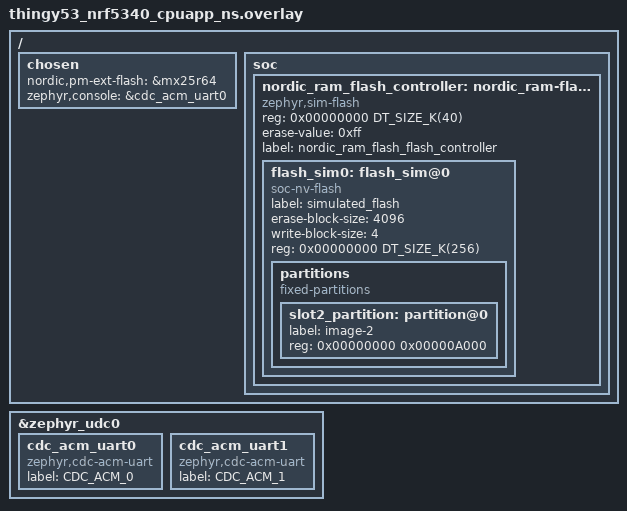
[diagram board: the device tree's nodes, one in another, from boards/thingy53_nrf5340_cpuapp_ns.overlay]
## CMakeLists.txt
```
#
# Copyright (c) 2018 Nordic Semiconductor
#
# SPDX-License-Identifier: LicenseRef-Nordic-5-Clause
#
cmake_minimum_required(VERSION 3.20.0)

find_package(Zephyr REQUIRED HINTS $ENV{ZEPHYR_BASE})
project(NONE)

# NORDIC SDK APP START
target_sources(app PRIVATE
  src/main.c
  src/protocol.c
  src/device_identification.c
  src/operation_command.c
  src/setting_command.c
  src/setting_command.c
  src/pressure_sensor.c
  deps/BMP180_driver/bmp180.c
)

# NORDIC SDK APP END

zephyr_library_include_directories(.)
zephyr_library_include_directories(deps)
```

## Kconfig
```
#
# Copyright (c) 2018 Nordic Semiconductor
#
# SPDX-License-Identifier: LicenseRef-Nordic-5-Clause
#

source "Kconfig.zephyr"

menu "Nordic UART BLE GATT service sample"

config BT_NUS_THREAD_STACK_SIZE
	int "Thread stack size"
	default 1024
	help
	  Stack size used in each of the two threads

config BT_NUS_UART_BUFFER_SIZE
	int "UART payload buffer element size"
	default 40
	help
	  Size of the payload buffer in each RX and TX FIFO element

config BT_NUS_SECURITY_ENABLED
	bool "Enable security"
	default y
	select BT_SMP
	help
	  "Enable BLE security for the UART service"

config BT_NUS_UART_DEV
	string "UART device name"
	default "UART_0"
	help
	  Name of the used UART device. The sample uses uart0 by default.
	  The UART device should not be used as logger backend.

config BT_NUS_UART_RX_WAIT_TIME
	int "Timeout for UART RX complete event"
	default 50
	help
	  Wait for RX complete event time in milliseconds

config BT_NUS_UART_ASYNC_ADAPTER
	bool "Enable UART async adapter"
	select SERIAL_SUPPORT_ASYNC
	help
	  Enables asynchronous adapter for UART drives that supports only
	  IRQ interface.

endmenu
```

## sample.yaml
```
sample:
  name: BLE UART service
  description: Bluetooth Low Energy UART service sample
tests:
  samples.bluetooth.peripheral_uart:
    build_only: true
    platform_allow: nrf51dk_nrf51422 nrf52dk_nrf52832 nrf52840dk_nrf52840
      nrf5340dk_nrf5340_cpuapp nrf5340dk_nrf5340_cpuapp_ns thingy53_nrf5340_cpuapp
      thingy53_nrf5340_cpuapp_ns nrf21540dk_nrf52840
    integration_platforms:
      - nrf51dk_nrf51422
      - nrf52dk_nrf52832
      - nrf52840dk_nrf52840
      - nrf5340dk_nrf5340_cpuapp
      - nrf5340dk_nrf5340_cpuapp_ns
      - thingy53_nrf5340_cpuapp
      - thingy53_nrf5340_cpuapp_ns
      - nrf21540dk_nrf52840
    tags: bluetooth ci_build
  samples.bluetooth.peripheral_uart_minimal:
    extra_args: OVERLAY_CONFIG=prj_minimal.conf
    build_only: true
    platform_allow: nrf52dk_nrf52810 nrf52840dk_nrf52811 nrf52833dk_nrf52820
    integration_platforms:
      - nrf52dk_nrf52810
      - nrf52840dk_nrf52811
      - nrf52833dk_nrf52820
    tags: bluetooth ci_build
  samples.bluetooth.peripheral_uart_cdc:
    extra_args: OVERLAY_CONFIG=prj_cdc.conf
                DTC_OVERLAY_FILE="usb.overlay"
    build_only: true
    platform_allow: nrf52840dk_nrf52840 nrf52833dk_nrf52833
    integration_platforms:
      - nrf52840dk_nrf52840
      - nrf52833dk_nrf52833
    tags: bluetooth ci_build
```

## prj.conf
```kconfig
#
# Copyright (c) 2018 Nordic Semiconductor
#
# SPDX-License-Identifier: LicenseRef-Nordic-5-Clause
#

# Enable the UART driver
CONFIG_UART_ASYNC_API=y
CONFIG_NRFX_UARTE0=y
CONFIG_SERIAL=y

# Enable the I2C driver
CONFIG_NRFX_TWI0=y
CONFIG_I2C=y

# Enable the PWM driver
CONFIG_NRFX_PWM0=y

CONFIG_GPIO=y

CONFIG_HEAP_MEM_POOL_SIZE=2048

CONFIG_BT=y
CONFIG_BT_PERIPHERAL=y
CONFIG_BT_DEVICE_NAME="Pressure Biofeedback App"
CONFIG_BT_DEVICE_APPEARANCE=833
CONFIG_BT_MAX_CONN=1
CONFIG_BT_MAX_PAIRED=1

# Enable the NUS service
CONFIG_BT_NUS=y
CONFIG_BT_NUS_SECURITY_ENABLED=n

# Enable bonding
CONFIG_BT_SETTINGS=y
CONFIG_FLASH=y
CONFIG_FLASH_PAGE_LAYOUT=y
CONFIG_FLASH_MAP=y
CONFIG_NVS=y
CONFIG_SETTINGS=y

# Enable DK LED and Buttons library
CONFIG_DK_LIBRARY=y

# This example requires more workqueue stack
CONFIG_SYSTEM_WORKQUEUE_STACK_SIZE=2048

# Config logger
CONFIG_LOG=y
CONFIG_USE_SEGGER_RTT=y
CONFIG_LOG_BACKEND_RTT=y
CONFIG_LOG_BACKEND_UART=n

CONFIG_ASSERT=y
```

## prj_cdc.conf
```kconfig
#
# Copyright (c) 2021 Nordic Semiconductor
#
# SPDX-License-Identifier: LicenseRef-Nordic-5-Clause
#

# Enable the UART driver
CONFIG_UART_LINE_CTRL=y
CONFIG_UART_INTERRUPT_DRIVEN=y
CONFIG_BT_NUS_UART_ASYNC_ADAPTER=y
CONFIG_USB_DEVICE_STACK=y
CONFIG_USB_CDC_ACM=y
CONFIG_BT_NUS_UART_DEV="CDC_ACM_0"

# Disable the UARTE0 enabled in default project configuration
CONFIG_NRFX_UARTE0=n
CONFIG_UART_NRFX=n
```

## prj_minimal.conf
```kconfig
#
# Copyright (c) 2021 Nordic Semiconductor
#
# SPDX-License-Identifier: LicenseRef-Nordic-5-Clause
#

# Enable the UART driver
CONFIG_UART_ASYNC_API=y
CONFIG_NRFX_UARTE0=y
CONFIG_SERIAL=y

CONFIG_HEAP_MEM_POOL_SIZE=2048

CONFIG_BT=y
CONFIG_BT_PERIPHERAL=y
CONFIG_BT_DEVICE_NAME="Nordic_UART_Service"
CONFIG_BT_DEVICE_APPEARANCE=833
CONFIG_BT_MAX_CONN=1
CONFIG_BT_MAX_PAIRED=1

# Enable the NUS service
CONFIG_BT_NUS=y

# Enable bonding
CONFIG_BT_SETTINGS=y
CONFIG_FLASH=y
CONFIG_FLASH_PAGE_LAYOUT=y
CONFIG_FLASH_MAP=y
CONFIG_NVS=y
CONFIG_SETTINGS=y

# Enable DK LED and Buttons library
CONFIG_DK_LIBRARY=y

# Drivers and peripherals
CONFIG_I2C=n
CONFIG_WATCHDOG=n
CONFIG_PINMUX=n
CONFIG_SPI=n
CONFIG_GPIO=n

# Power management
CONFIG_PM=n

# Interrupts
CONFIG_DYNAMIC_INTERRUPTS=n
CONFIG_IRQ_OFFLOAD=n

# Memory protection
CONFIG_THREAD_STACK_INFO=n
CONFIG_THREAD_CUSTOM_DATA=n
CONFIG_FPU=n

# Boot
CONFIG_BOOT_BANNER=n
CONFIG_BOOT_DELAY=0

# Console
CONFIG_CONSOLE=n
CONFIG_UART_CONSOLE=n
CONFIG_STDOUT_CONSOLE=n
CONFIG_PRINTK=n
CONFIG_EARLY_CONSOLE=n

# Build
CONFIG_SIZE_OPTIMIZATIONS=y

# ARM
CONFIG_ARM_MPU=n

# In order to correctly tune the stack sizes for the threads the following
# Configurations can enabled to print the current use:
#CONFIG_THREAD_NAME=y
#CONFIG_THREAD_ANALYZER=y
#CONFIG_THREAD_ANALYZER_AUTO=y
#CONFIG_THREAD_ANALYZER_RUN_UNLOCKED=y
#CONFIG_THREAD_ANALYZER_USE_PRINTK=y
#CONFIG_CONSOLE=y
#CONFIG_UART_CONSOLE=y
#CONFIG_SERIAL=y
#CONFIG_PRINTK=y

# Example output of thread analyzer
#SDC RX              : unused 800 usage 224 / 1024 (21 %)
#BT ECC              : unused 216 usage 888 / 1104 (80 %)
#BT RX               : unused 1736 usage 464 / 2200 (21 %)
#BT TX               : unused 1008 usage 528 / 1536 (34 %)
#ble_write_thread_id : unused 688 usage 336 / 1024 (32 %)
#sysworkq            : unused 1912 usage 136 / 2048 (6 %)
#MPSL signal         : unused 928 usage 96 / 1024 (9 %)
#idle 00             : unused 224 usage 96 / 320 (30 %)
#main                : unused 568 usage 456 / 1024 (44 %)
CONFIG_BT_CTLR_SDC_RX_STACK_SIZE=324
CONFIG_BT_RX_STACK_SIZE=1024
CONFIG_BT_HCI_TX_STACK_SIZE_WITH_PROMPT=y
CONFIG_BT_HCI_TX_STACK_SIZE=640
CONFIG_SYSTEM_WORKQUEUE_STACK_SIZE=512
CONFIG_MPSL_SIGNAL_STACK_SIZE=256
CONFIG_MAIN_STACK_SIZE=640
CONFIG_IDLE_STACK_SIZE=128
CONFIG_ISR_STACK_SIZE=1024
CONFIG_BT_NUS_THREAD_STACK_SIZE=512

# Disable features not needed
CONFIG_TIMESLICING=n
CONFIG_MINIMAL_LIBC_MALLOC=n
CONFIG_LOG=n
CONFIG_ASSERT=n

# Disable Bluetooth features not needed
CONFIG_BT_DEBUG_NONE=y
CONFIG_BT_ASSERT=n
CONFIG_BT_DATA_LEN_UPDATE=n
CONFIG_BT_PHY_UPDATE=n
CONFIG_BT_GATT_CACHING=n
CONFIG_BT_GATT_SERVICE_CHANGED=n
CONFIG_BT_GAP_PERIPHERAL_PREF_PARAMS=n
CONFIG_BT_SETTINGS_CCC_LAZY_LOADING=y
CONFIG_BT_HCI_VS_EXT=n

# Disable Bluetooth controller features not needed
CONFIG_BT_CTLR_PRIVACY=n
CONFIG_BT_CTLR_PHY_2M=n

# Reduce Bluetooth buffers
CONFIG_BT_BUF_EVT_DISCARDABLE_COUNT=1
CONFIG_BT_BUF_EVT_DISCARDABLE_SIZE=43
CONFIG_BT_BUF_EVT_RX_COUNT=2

CONFIG_BT_CONN_TX_MAX=2
CONFIG_BT_L2CAP_TX_BUF_COUNT=2
CONFIG_BT_CTLR_RX_BUFFERS=1
CONFIG_BT_BUF_ACL_TX_COUNT=3
CONFIG_BT_BUF_ACL_TX_SIZE=27
```

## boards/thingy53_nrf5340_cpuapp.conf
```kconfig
#
# Copyright (c) 2021 Nordic Semiconductor ASA
#
# SPDX-License-Identifier: LicenseRef-Nordic-5-Clause
#
################################################################################
# Application overlay - Thingy:53 DFU

CONFIG_MCUMGR=y
CONFIG_MCUMGR_SMP_BT=y
CONFIG_MCUMGR_SMP_BT_AUTHEN=n
CONFIG_MCUMGR_SMP_BT_CONN_PARAM_CONTROL=y

CONFIG_MCUMGR_CMD_IMG_MGMT=y
CONFIG_MCUMGR_CMD_OS_MGMT=y

# Enable custom SMP request to erase settings partition.
CONFIG_MCUMGR_GRP_ZEPHYR_BASIC=y
CONFIG_MCUMGR_GRP_BASIC_CMD_STORAGE_ERASE=y

# Increase system workqueue stack size to prevent stack overflows while handling
# SMP requests.
CONFIG_SYSTEM_WORKQUEUE_STACK_SIZE=2800

CONFIG_BT_L2CAP_TX_MTU=498
CONFIG_BT_BUF_ACL_TX_SIZE=251
CONFIG_BT_BUF_ACL_RX_SIZE=502

# Use connection parameters that ensure quick data transfer
CONFIG_BT_PERIPHERAL_PREF_MIN_INT=6
CONFIG_BT_PERIPHERAL_PREF_MAX_INT=6
CONFIG_BT_PERIPHERAL_PREF_LATENCY=99
CONFIG_BT_PERIPHERAL_PREF_TIMEOUT=400

# LEDs are not inverted on Thingy:53
CONFIG_DK_LIBRARY_INVERT_LEDS=n

################################################################################
# Bootloader configuration

CONFIG_BOOTLOADER_MCUBOOT=y
CONFIG_MCUBOOT_IMAGE_VERSION="1.0.0+0"
CONFIG_UPDATEABLE_IMAGE_NUMBER=2

CONFIG_IMG_MANAGER=y
CONFIG_MCUBOOT_IMG_MANAGER=y
CONFIG_IMG_ERASE_PROGRESSIVELY=y

################################################################################
# External flash configuration

CONFIG_NORDIC_QSPI_NOR=y
CONFIG_NORDIC_QSPI_NOR_FLASH_LAYOUT_PAGE_SIZE=4096
CONFIG_NORDIC_QSPI_NOR_STACK_WRITE_BUFFER_SIZE=16

# FLASH nop device is enabled to prevent bus faults when mcumgr tries to access
# simulated partition with network core image data.
CONFIG_FLASH_NOP_DEVICE=y

################################################################################
# Enable USB CDC ACM

CONFIG_USB_DEVICE_STACK=y
CONFIG_USB_DEVICE_PRODUCT="Thingy:53 Nordic UART Service sample"
CONFIG_USB_DEVICE_VID=0x1915
CONFIG_USB_DEVICE_PID=0x530E
CONFIG_USB_COMPOSITE_DEVICE=y
CONFIG_USB_CDC_ACM=y
CONFIG_USB_CDC_ACM_LOG_LEVEL_ERR=y
CONFIG_USB_DEVICE_LOG_LEVEL_ERR=y

CONFIG_LOG_BACKEND_UART=y
CONFIG_LOG_PRINTK=y
CONFIG_LOG_PROCESS_THREAD_STACK_SIZE=1024
CONFIG_LOG_PROCESS_THREAD_STARTUP_DELAY_MS=4000
CONFIG_USE_SEGGER_RTT=n
CONFIG_LOG_BACKEND_RTT=n

CONFIG_BT_NUS_UART_ASYNC_ADAPTER=y
CONFIG_BT_NUS_UART_DEV="CDC_ACM_1"
CONFIG_UART_INTERRUPT_DRIVEN=y

# Disable the UARTE0 enabled in default project configuration
CONFIG_NRFX_UARTE0=n
CONFIG_UART_NRFX=n
```

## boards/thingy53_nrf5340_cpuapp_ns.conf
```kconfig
#
# Copyright (c) 2021 Nordic Semiconductor ASA
#
# SPDX-License-Identifier: LicenseRef-Nordic-5-Clause
#
################################################################################
# Application overlay - Thingy:53 DFU

CONFIG_MCUMGR=y
CONFIG_MCUMGR_SMP_BT=y
CONFIG_MCUMGR_SMP_BT_AUTHEN=n
CONFIG_MCUMGR_SMP_BT_CONN_PARAM_CONTROL=y

CONFIG_MCUMGR_CMD_IMG_MGMT=y
CONFIG_MCUMGR_CMD_OS_MGMT=y

# Enable MCUmgr Packet Reassembly feature over Bluetooth and its
# configuration dependencies. MCUmgr buffer size is optimized to fit one SMP
# packet divided into five Bluetooth Write Commands, transmitted with the
# maximum possible MTU value: 498 bytes.
CONFIG_MCUMGR_SMP_REASSEMBLY_BT=y
CONFIG_MCUMGR_BUF_SIZE=2475
CONFIG_OS_MGMT_MCUMGR_PARAMS=y

# Enable custom SMP request to erase settings partition.
CONFIG_MCUMGR_GRP_ZEPHYR_BASIC=y
CONFIG_MCUMGR_GRP_BASIC_CMD_STORAGE_ERASE=y

# Increase system workqueue stack size to prevent stack overflows while handling
# SMP requests.
CONFIG_SYSTEM_WORKQUEUE_STACK_SIZE=4096

CONFIG_BT_L2CAP_TX_MTU=498
CONFIG_BT_BUF_ACL_TX_SIZE=251
CONFIG_BT_BUF_ACL_RX_SIZE=502

# Use connection parameters that ensure quick data transfer
CONFIG_BT_PERIPHERAL_PREF_MIN_INT=6
CONFIG_BT_PERIPHERAL_PREF_MAX_INT=6
CONFIG_BT_PERIPHERAL_PREF_LATENCY=99
CONFIG_BT_PERIPHERAL_PREF_TIMEOUT=400

################################################################################
# Bootloader configuration

CONFIG_BOOTLOADER_MCUBOOT=y
CONFIG_MCUBOOT_IMAGE_VERSION="2.0.0+0"
CONFIG_UPDATEABLE_IMAGE_NUMBER=2

CONFIG_IMG_MANAGER=y
CONFIG_MCUBOOT_IMG_MANAGER=y
CONFIG_IMG_ERASE_PROGRESSIVELY=y

################################################################################
# External flash configuration

CONFIG_NORDIC_QSPI_NOR=y
CONFIG_NORDIC_QSPI_NOR_FLASH_LAYOUT_PAGE_SIZE=4096
CONFIG_NORDIC_QSPI_NOR_STACK_WRITE_BUFFER_SIZE=16

################################################################################
# Enable USB CDC ACM

CONFIG_USB_DEVICE_STACK=y
CONFIG_USB_DEVICE_REMOTE_WAKEUP=n
CONFIG_USB_DEVICE_PRODUCT="Thingy:53 Nordic UART Service sample"
CONFIG_USB_DEVICE_VID=0x1915
CONFIG_USB_DEVICE_PID=0x530E
CONFIG_USB_COMPOSITE_DEVICE=y
CONFIG_USB_CDC_ACM=y
CONFIG_USB_CDC_ACM_LOG_LEVEL_ERR=y
CONFIG_USB_DEVICE_LOG_LEVEL_ERR=y

CONFIG_LOG_BACKEND_UART=y
CONFIG_LOG_PRINTK=y
CONFIG_LOG_PROCESS_THREAD_STACK_SIZE=1024
CONFIG_LOG_PROCESS_THREAD_STARTUP_DELAY_MS=4000
CONFIG_USE_SEGGER_RTT=n
CONFIG_LOG_BACKEND_RTT=n

CONFIG_BT_NUS_UART_ASYNC_ADAPTER=y
CONFIG_UART_INTERRUPT_DRIVEN=y

# Disable the UARTE0 enabled in default project configuration
CONFIG_NRFX_UARTE0=n
CONFIG_UART_NRFX=n
```

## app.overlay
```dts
/*
 * Copyright (c) 2022 Nordic Semiconductor ASA
 *
 * SPDX-License-Identifier: LicenseRef-Nordic-5-Clause
 */

/ {
	chosen {
		nordic,nus-uart = &uart0;
	};

    buttons {
        status = "disabled"; /* to avoid  */
    };
};

&i2c0 {
    compatible = "nordic,nrf-twim";
};

&pinctrl {
    i2c0_default: i2c0_default {
        group1 {
            psels = <NRF_PSEL(TWIM_SDA, 0, 12)>,
                <NRF_PSEL(TWIM_SCL, 0, 11)>;
        };
    };
    i2c0_sleep: i2c0_sleep {
        group1 {
            psels = <NRF_PSEL(TWIM_SDA, 0, 12)>,
                <NRF_PSEL(TWIM_SCL, 0, 11)>;
            low-power-enable;
        };
    };
};
```

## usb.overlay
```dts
/*
 * Copyright (c) 2021 Nordic Semiconductor ASA
 *
 * SPDX-License-Identifier: LicenseRef-Nordic-5-Clause
 */

/ {
	chosen {
		zephyr,console = &cdc_acm_uart0;
	};
};

&zephyr_udc0 {
	cdc_acm_uart0: cdc_acm_uart0 {
		compatible = "zephyr,cdc-acm-uart";
		label = "CDC_ACM_0";
	};
};
```

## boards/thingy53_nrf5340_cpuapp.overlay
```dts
/*
 * Copyright (c) 2021 Nordic Semiconductor ASA
 *
 * SPDX-License-Identifier: LicenseRef-Nordic-5-Clause
 */

/ {
	chosen {
		nordic,pm-ext-flash = &mx25r64;
	};
};

/ {
	chosen {
		zephyr,console = &cdc_acm_uart0;
		nordic,nus-uart = &cdc_acm_uart1;
	};
};

&zephyr_udc0 {
	cdc_acm_uart0: cdc_acm_uart0 {
		compatible = "zephyr,cdc-acm-uart";
	};

	cdc_acm_uart1: cdc_acm_uart1 {
		compatible = "zephyr,cdc-acm-uart";
	};
};
```

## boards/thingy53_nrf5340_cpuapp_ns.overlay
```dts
/*
 * Copyright (c) 2021 Nordic Semiconductor ASA
 *
 * SPDX-License-Identifier: LicenseRef-Nordic-5-Clause
 */

/ {
	chosen {
		nordic,pm-ext-flash = &mx25r64;
	};
};

/*
 * This file is used to enable a partition which is used through the flash API
 * but which is in reality stored in RAM. This is done to load data from
 * external flash to the network core. Since the network core cannot access
 * the external flash directly, the data is buffered in RAM before being
 * copied by the network core to the network core flash.
 *
 * The partition must be enabled by the application configuration to prevent
 * bus faults when mcumgr tries to access simulated partition with network core
 * image data.
 */

/ {
	soc {
		/* Add a flash controller which has the compatible
		 * 'zephyr,sim-flash'. This will ensure that the flash
		 * simulator can use it. None of the other properties in this
		 * node is used for anything.
		 */
		nordic_ram_flash_controller: nordic_ram-flash-controller@0 {
			compatible = "zephyr,sim-flash";
			reg = <0x00000000 DT_SIZE_K(40)>;
			#address-cells = <1>;
			#size-cells = <1>;
			erase-value = <0xff>;
			label = "nordic_ram_flash_flash_controller";

			/* This node label must match that used in the flash
			 * simulator.
			 */
			flash_sim0: flash_sim@0 {
				status = "okay";
				compatible = "soc-nv-flash";
				label = "simulated_flash";
				erase-block-size = <4096>;
				write-block-size = <4>;
				reg = <0x00000000 DT_SIZE_K(256)>;

				partitions {
					compatible = "fixed-partitions";
					#address-cells = <1>;
					#size-cells = <1>;

					/* This partition must be defined for
					 * MCUboot to find the partition ID
					 * of the primary slot for image 1,
					 * which is stored in this partition.
					 */
					slot2_partition: partition@0 {
						label = "image-2";
						reg = <0x00000000 0x00000A000>;
					};
				};
			};
		};
	};

	chosen {
		zephyr,console = &cdc_acm_uart0;
	};
};

&zephyr_udc0 {
	cdc_acm_uart0: cdc_acm_uart0 {
		compatible = "zephyr,cdc-acm-uart";
		label = "CDC_ACM_0";
	};

	cdc_acm_uart1: cdc_acm_uart1 {
		compatible = "zephyr,cdc-acm-uart";
		label = "CDC_ACM_1";
	};
};
```

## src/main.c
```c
/*
 * Copyright (c) 2018 Nordic Semiconductor ASA
 *
 * SPDX-License-Identifier: LicenseRef-Nordic-5-Clause
 */

/** @file
 *  @brief Nordic UART Bridge Service (NUS) sample
 */

#include <zephyr/types.h>
#include <zephyr/kernel.h>

#include <zephyr/device.h>
#include <zephyr/devicetree.h>
#include <soc.h>

#include <zephyr/bluetooth/bluetooth.h>
#include <zephyr/bluetooth/uuid.h>
#include <zephyr/bluetooth/gatt.h>
#include <zephyr/bluetooth/hci.h>

#include <bluetooth/services/nus.h>

#include <dk_buttons_and_leds.h>

#include <zephyr/settings/settings.h>

#include <stdio.h>

#include <zephyr/logging/log.h>

#include "protocol.h"
#include "device_identification.h"
#include "operation_command.h"
#include "setting_command.h"

#define LOG_MODULE_NAME peripheral_uart
LOG_MODULE_REGISTER(LOG_MODULE_NAME);

#define STACKSIZE CONFIG_BT_NUS_THREAD_STACK_SIZE
#define PRIORITY 7

#define DEVICE_NAME CONFIG_BT_DEVICE_NAME
#define DEVICE_NAME_LEN	(sizeof(DEVICE_NAME) - 1)

#define RUN_STATUS_LED DK_LED1
#define RUN_LED_BLINK_INTERVAL 1000

#define CON_STATUS_LED DK_LED2

#define KEY_PASSKEY_ACCEPT DK_BTN1_MSK
#define KEY_PASSKEY_REJECT DK_BTN2_MSK

#define BT_BUF_SIZE CONFIG_BT_NUS_UART_BUFFER_SIZE

static K_SEM_DEFINE(ble_init_ok, 0, 1);

static struct bt_conn *current_conn;
static struct bt_conn *auth_conn;

struct bt_data_t {
	void *fifo_reserved;
	uint8_t data[BT_BUF_SIZE];
	uint16_t len;
};

static K_FIFO_DEFINE(fifo_bt_data);

static const struct bt_data ad[] = {
	BT_DATA_BYTES(BT_DATA_FLAGS, (BT_LE_AD_GENERAL | BT_LE_AD_NO_BREDR)),
	BT_DATA(BT_DATA_NAME_COMPLETE, DEVICE_NAME, DEVICE_NAME_LEN),
};

static const struct bt_data sd[] = {
	BT_DATA_BYTES(BT_DATA_UUID128_ALL, BT_UUID_NUS_VAL),
};

static void connected(struct bt_conn *conn, uint8_t err)
{
	char addr[BT_ADDR_LE_STR_LEN];

	if (err) {
		LOG_ERR("Connection failed (err %u)", err);
		return;
	}

	bt_addr_le_to_str(bt_conn_get_dst(conn), addr, sizeof(addr));
	LOG_INF("Connected %s", addr);

	current_conn = bt_conn_ref(conn);

	// dk_set_led_on(CON_STATUS_LED);
}

static void disconnected(struct bt_conn *conn, uint8_t reason)
{
	char addr[BT_ADDR_LE_STR_LEN];

	bt_addr_le_to_str(bt_conn_get_dst(conn), addr, sizeof(addr));

	LOG_INF("Disconnected: %s (reason %u)", addr, reason);

	if (auth_conn) {
		bt_conn_unref(auth_conn);
		auth_conn = NULL;
	}

	if (current_conn) {
		bt_conn_unref(current_conn);
		current_conn = NULL;
		// dk_set_led_off(CON_STATUS_LED);
	}
}

BT_CONN_CB_DEFINE(conn_callbacks) = {
	.connected    = connected,
	.disconnected = disconnected,
};

static void bt_receive_cb(struct bt_conn *conn, const uint8_t *const data,
			  uint16_t len)
{
	char addr[BT_ADDR_LE_STR_LEN] = {0};

	bt_addr_le_to_str(bt_conn_get_dst(conn), addr, ARRAY_SIZE(addr));

	LOG_INF("Received data from: %s", addr);

	for (uint16_t pos = 0; pos != len;) {
		struct bt_data_t *tx = k_malloc(sizeof(*tx));

		if (!tx) {
			LOG_WRN("Not able to allocate data buffer");
			return;
		}

		/* Keep the last byte of TX buffer for potential LF char. */
		size_t tx_data_size = sizeof(tx->data) - 1;

		if ((len - pos) > tx_data_size) {
			tx->len = tx_data_size;
		} else {
			tx->len = (len - pos);
		}

		memcpy(tx->data, &data[pos], tx->len);

		pos += tx->len;

		/* Append the LF character when the CR character triggered
		 * transmission from the peer.
		 */
		if ((pos == len) && (data[len - 1] == '\r')) {
			tx->data[tx->len] = '\n';
			tx->len++;
		}

        k_fifo_put(&fifo_bt_data, tx);
	}
}

static struct bt_nus_cb nus_cb = {
	.received = bt_receive_cb,
};

void error(void)
{
	// dk_set_leds_state(DK_ALL_LEDS_MSK, DK_NO_LEDS_MSK);

	while (true) {
		/* Spin for ever */
		k_sleep(K_MSEC(1000));
	}
}

#include <hal/nrf_gpio.h>
#define STAT1_PIN   43
#define STAT2_PIN   44
#define AC_PG_PIN   45
#define USB_PG_PIN  46

static void configure_gpio(void)
{
	int err;

    nrf_gpio_cfg_input(STAT1_PIN, GPIO_PIN_CNF_PULL_Pullup);
    nrf_gpio_cfg_input(STAT2_PIN, GPIO_PIN_CNF_PULL_Pullup);
    nrf_gpio_cfg_input(AC_PG_PIN, GPIO_PIN_CNF_PULL_Pullup);
    nrf_gpio_cfg_input(USB_PG_PIN, GPIO_PIN_CNF_PULL_Pullup);

	err = dk_leds_init();
	if (err) {
		LOG_ERR("Cannot init LEDs (err: %d)", err);
	}
}

extern void PressureSensor_init(void);

void measure(struct k_timer *dummy)
{
	extern uint8_t PressureSensor_read(void);
    uint8_t data = PressureSensor_read();

    uint8_t command[] = {0x11, 0xEE, data, ~data};
    bt_receive_cb(NULL, command, sizeof(command));
}

int measure_handler(ProtocolDataUnit *pdu)
{
    return 0;
}

void main(void)
{
	int blink_status = 0;
	int err = 0;

	configure_gpio();
    SettingCommand_init();
    Protocol_set_handler(
        COMMAND_MEASURED_DATA,
        &(ProtocolHandler) {
            .command = 0x11EE,
            .handler = measure_handler
        }
    );
    PressureSensor_init();
    OperationCommand_init();
    DeviceIdentification_init();

	err = bt_enable(NULL);
	if (err) {
		error();
	}

	LOG_INF("Bluetooth initialized");

	k_sem_give(&ble_init_ok);

	if (IS_ENABLED(CONFIG_SETTINGS)) {
		settings_load();
	}

	err = bt_nus_init(&nus_cb);
	if (err) {
		LOG_ERR("Failed to initialize UART service (err: %d)", err);
		return;
	}

	err = bt_le_adv_start(BT_LE_ADV_CONN, ad, ARRAY_SIZE(ad), sd,
			      ARRAY_SIZE(sd));
	if (err) {
		LOG_ERR("Advertising failed to start (err %d)", err);
		return;
	}

	for (;;) {
		dk_set_led(RUN_STATUS_LED, (++blink_status) % 2);
		k_sleep(K_MSEC(RUN_LED_BLINK_INTERVAL));
	}
}

void ble_write_thread(void)
{
	/* Don't go any further until BLE is initialized */
	k_sem_take(&ble_init_ok, K_FOREVER);

	for (;;) {
		/* Wait indefinitely for data to be sent over bluetooth */
		struct bt_data_t *buf = k_fifo_get(&fifo_bt_data, K_FOREVER);
        ProtocolDataUnit *pdu = Protocol_new_pdu(buf->data, buf->len);
        if (!pdu) {
            goto cleanup;
        }
        if (Protocol_handle(pdu)) {
            goto cleanup;
        }
		if (bt_nus_send(NULL, buf->data, buf->len)) {
			LOG_WRN("Failed to send data over BLE connection");
		}
cleanup:
        Protocol_delete_pdu(pdu);
		k_free(buf);
	}
}

K_THREAD_DEFINE(ble_write_thread_id, STACKSIZE, ble_write_thread, NULL, NULL,
		NULL, PRIORITY, 0, 0);
```

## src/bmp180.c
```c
/**
* Copyright (c) 2020 Bosch Sensortec GmbH. All rights reserved.
*
* BSD-3-Clause
*
* Redistribution and use in source and binary forms, with or without
* modification, are permitted provided that the following conditions are met:
*
* 1. Redistributions of source code must retain the above copyright
*    notice, this list of conditions and the following disclaimer.
*
* 2. Redistributions in binary form must reproduce the above copyright
*    notice, this list of conditions and the following disclaimer in the
*    documentation and/or other materials provided with the distribution.
*
* 3. Neither the name of the copyright holder nor the names of its
*    contributors may be used to endorse or promote products derived from
*    this software without specific prior written permission.
*
* THIS SOFTWARE IS PROVIDED BY THE COPYRIGHT HOLDERS AND CONTRIBUTORS
* "AS IS" AND ANY EXPRESS OR IMPLIED WARRANTIES, INCLUDING, BUT NOT
* LIMITED TO, THE IMPLIED WARRANTIES OF MERCHANTABILITY AND FITNESS
* FOR A PARTICULAR PURPOSE ARE DISCLAIMED. IN NO EVENT SHALL THE
* COPYRIGHT HOLDER OR CONTRIBUTORS BE LIABLE FOR ANY DIRECT, INDIRECT,
* INCIDENTAL, SPECIAL, EXEMPLARY, OR CONSEQUENTIAL DAMAGES
* (INCLUDING, BUT NOT LIMITED TO, PROCUREMENT OF SUBSTITUTE GOODS OR
* SERVICES; LOSS OF USE, DATA, OR PROFITS; OR BUSINESS INTERRUPTION)
* HOWEVER CAUSED AND ON ANY THEORY OF LIABILITY, WHETHER IN CONTRACT,
* STRICT LIABILITY, OR TORT (INCLUDING NEGLIGENCE OR OTHERWISE) ARISING
* IN ANY WAY OUT OF THE USE OF THIS SOFTWARE, EVEN IF ADVISED OF THE
* POSSIBILITY OF SUCH DAMAGE.
*
* @file bmp180.c
* @date 10/01/2020
* @version  2.2.5
*
*/

#include "bmp180.h"
static struct bmp180_t *p_bmp180;

/*!
 *  @brief This function is used for initialize
 *  the bus read and bus write functions
 *  and assign the chip id and I2C address of the BMP180
 *  chip id is read in the register 0xD0 bit from 0 to 7
 *
 *   @param bmp180 structure pointer.
 *
 *  @note While changing the parameter of the bmp180_t
 *  @note consider the following point:
 *  Changing the reference value of the parameter
 *  will changes the local copy or local reference
 *  make sure your changes will not
 *  affect the reference value of the parameter
 *  (Better case don't change the reference value of the parameter)
 *
 *
 *
 *
 *  @return results of bus communication function
 *  @retval 0 -> Success
 *  @retval -1 -> Error
 *
 *
 */
BMP180_RETURN_FUNCTION_TYPE bmp180_init(struct bmp180_t *bmp180)
{
    /* used to return the bus communication results*/
    BMP180_RETURN_FUNCTION_TYPE v_com_rslt_s8 = E_BMP_COMM_RES;
    u8 v_data_u8 = BMP180_INIT_VALUE;

    /* assign BMP180 ptr */
    p_bmp180 = bmp180;

    /* read Chip Id */
    v_com_rslt_s8 = p_bmp180->BMP180_BUS_READ_FUNC(p_bmp180->dev_addr,
                                                   BMP180_CHIP_ID__REG,
                                                   &v_data_u8,
                                                   BMP180_GEN_READ_WRITE_DATA_LENGTH);
    p_bmp180->chip_id = BMP180_GET_BITSLICE(v_data_u8, BMP180_CHIP_ID);
    p_bmp180->number_of_samples = BMP180_INITIALIZE_NUMBER_OF_SAMPLES_U8X;
    p_bmp180->oversamp_setting = BMP180_INITIALIZE_OVERSAMP_SETTING_U8X;
    p_bmp180->sw_oversamp = BMP180_INITIALIZE_SW_OVERSAMP_U8X;
    v_com_rslt_s8 += p_bmp180->BMP180_BUS_READ_FUNC(p_bmp180->dev_addr,
                                                    BMP180_VERSION_REG,
                                                    &v_data_u8,
                                                    BMP180_GEN_READ_WRITE_DATA_LENGTH);

    /* read Version reg */
    p_bmp180->ml_version = BMP180_GET_BITSLICE(v_data_u8, BMP180_ML_VERSION); /* get ML version */
    p_bmp180->al_version = BMP180_GET_BITSLICE(v_data_u8, BMP180_AL_VERSION); /* get AL version */
    v_com_rslt_s8 += bmp180_get_calib_param();

    return v_com_rslt_s8;
}

/*!
 *  @brief this function used for read the calibration
 *  parameter from the register
 *
 *  Parameter  |  MSB    |  LSB    |  bit
 * ------------|---------|---------|-----------
 *      AC1    |  0xAA   | 0xAB    | 0 to 7
 *      AC2    |  0xAC   | 0xAD    | 0 to 7
 *      AC3    |  0xAE   | 0xAF    | 0 to 7
 *      AC4    |  0xB0   | 0xB1    | 0 to 7
 *      AC5    |  0xB2   | 0xB3    | 0 to 7
 *      AC6    |  0xB4   | 0xB5    | 0 to 7
 *      B1     |  0xB6   | 0xB7    | 0 to 7
 *      B2     |  0xB8   | 0xB9    | 0 to 7
 *      MB     |  0xBA   | 0xBB    | 0 to 7
 *      MC     |  0xBC   | 0xBD    | 0 to 7
 *      MD     | 0xBE    | 0xBF    | 0 to 7
 *
 *
 *  @return results of bus communication function
 *  @retval 0 -> Success
 *  @retval -1 -> Error
 *
 *
 */
BMP180_RETURN_FUNCTION_TYPE bmp180_get_calib_param(void)
{
    /* used to return the bus communication results*/
    BMP180_RETURN_FUNCTION_TYPE v_com_rslt_s8 = E_BMP_COMM_RES;

    /* Array holding the calibration informations*/
    u8 a_data_u8r[BMP180_CALIB_DATA_SIZE] = {
        BMP180_INIT_VALUE, BMP180_INIT_VALUE, BMP180_INIT_VALUE, BMP180_INIT_VALUE, BMP180_INIT_VALUE,
        BMP180_INIT_VALUE, BMP180_INIT_VALUE, BMP180_INIT_VALUE, BMP180_INIT_VALUE, BMP180_INIT_VALUE,
        BMP180_INIT_VALUE, BMP180_INIT_VALUE, BMP180_INIT_VALUE, BMP180_INIT_VALUE, BMP180_INIT_VALUE,
        BMP180_INIT_VALUE, BMP180_INIT_VALUE, BMP180_INIT_VALUE, BMP180_INIT_VALUE, BMP180_INIT_VALUE,
        BMP180_INIT_VALUE, BMP180_INIT_VALUE
    };

    /* read calibration data*/
    v_com_rslt_s8 = p_bmp180->BMP180_BUS_READ_FUNC(p_bmp180->dev_addr,
                                                   BMP180_PROM_START__ADDR,
                                                   a_data_u8r,
                                                   BMP180_PROM_DATA__LEN);

    /*parameters AC1-AC6*/
    p_bmp180->calib_param.ac1 =
        (s16)((((s32)((s8)a_data_u8r[BMP180_CALIB_PARAM_AC1_MSB])) << BMP180_SHIFT_BIT_POSITION_BY_08_BITS) |
              a_data_u8r[BMP180_CALIB_PARAM_AC1_LSB]);
    p_bmp180->calib_param.ac2 =
        (s16)((((s32)((s8)a_data_u8r[BMP180_CALIB_PARAM_AC2_MSB])) << BMP180_SHIFT_BIT_POSITION_BY_08_BITS) |
              a_data_u8r[BMP180_CALIB_PARAM_AC2_LSB]);
    p_bmp180->calib_param.ac3 =
        (s16)((((s32)((s8)a_data_u8r[BMP180_CALIB_PARAM_AC3_MSB])) << BMP180_SHIFT_BIT_POSITION_BY_08_BITS) |
              a_data_u8r[BMP180_CALIB_PARAM_AC3_LSB]);
    p_bmp180->calib_param.ac4 =
        (u16)((((u32)((u8)a_data_u8r[BMP180_CALIB_PARAM_AC4_MSB])) << BMP180_SHIFT_BIT_POSITION_BY_08_BITS) |
              a_data_u8r[BMP180_CALIB_PARAM_AC4_LSB]);
    p_bmp180->calib_param.ac5 =
        (u16)((((u32)((u8)a_data_u8r[BMP180_CALIB_PARAM_AC5_MSB])) << BMP180_SHIFT_BIT_POSITION_BY_08_BITS) |
              a_data_u8r[BMP180_CALIB_PARAM_AC5_LSB]);
    p_bmp180->calib_param.ac6 =
        (u16)((((u32)((u8)a_data_u8r[BMP180_CALIB_PARAM_AC6_MSB])) << BMP180_SHIFT_BIT_POSITION_BY_08_BITS) |
              a_data_u8r[BMP180_CALIB_PARAM_AC6_LSB]);

    /*parameters B1,B2*/
    p_bmp180->calib_param.b1 =
        (s16)((((s32)((s8)a_data_u8r[BMP180_CALIB_PARAM_B1_MSB])) << BMP180_SHIFT_BIT_POSITION_BY_08_BITS) |
              a_data_u8r[BMP180_CALIB_PARAM_B1_LSB]);
    p_bmp180->calib_param.b2 =
        (s16)((((s32)((s8)a_data_u8r[BMP180_CALIB_PARAM_B2_MSB])) << BMP180_SHIFT_BIT_POSITION_BY_08_BITS) |
              a_data_u8r[BMP180_CALIB_PARAM_B2_LSB]);

    /*parameters MB,MC,MD*/
    p_bmp180->calib_param.mb =
        (s16)((((s32)((s8)a_data_u8r[BMP180_CALIB_PARAM_MB_MSB])) << BMP180_SHIFT_BIT_POSITION_BY_08_BITS) |
              a_data_u8r[BMP180_CALIB_PARAM_MB_LSB]);
    p_bmp180->calib_param.mc =
        (s16)((((s32)((s8)a_data_u8r[BMP180_CALIB_PARAM_MC_MSB])) << BMP180_SHIFT_BIT_POSITION_BY_08_BITS) |
              a_data_u8r[BMP180_CALIB_PARAM_MC_LSB]);
    p_bmp180->calib_param.md =
        (s16)((((s32)((s8)a_data_u8r[BMP180_CALIB_PARAM_MD_MSB])) << BMP180_SHIFT_BIT_POSITION_BY_08_BITS) |
              a_data_u8r[BMP180_CALIB_PARAM_MD_LSB]);

    return v_com_rslt_s8;
}

/*!
 *  @brief this API is used to calculate the true
 *  temperature using the uncompensated temperature(ut)
 *  @note For reading the ut data refer : bmp180_read_ut()
 *
 *  @param v_uncomp_temperature_u32:
 *  the value of uncompensated temperature
 *
 *  @return Return the temperature in steps of 0.1 deg Celsius
 *
 *
 */
s16 bmp180_get_temperature(u32 v_uncomp_temperature_u32)
{
    s16 v_temperature_s16 = BMP180_INIT_VALUE;
    s32 v_x1_s32, v_x2_s32 = BMP180_INIT_VALUE;

    /* calculate temperature*/
    v_x1_s32 = (((s32) v_uncomp_temperature_u32 - (s32) p_bmp180->calib_param.ac6) * (s32) p_bmp180->calib_param.ac5) >>
               BMP180_SHIFT_BIT_POSITION_BY_15_BITS;
    if (v_x1_s32 == BMP180_CHECK_DIVISOR && p_bmp180->calib_param.md == BMP180_CHECK_DIVISOR)
    {
        return BMP180_INVALID_DATA;
    }

    /* executed only the divisor is not zero*/
    v_x2_s32 = ((s32) p_bmp180->calib_param.mc << BMP180_SHIFT_BIT_POSITION_BY_11_BITS) /
               (v_x1_s32 + p_bmp180->calib_param.md);
    p_bmp180->param_b5 = v_x1_s32 + v_x2_s32;
    v_temperature_s16 =
        ((p_bmp180->param_b5 + BMP180_CALCULATE_TRUE_TEMPERATURE) >> BMP180_SHIFT_BIT_POSITION_BY_04_BITS);

    return v_temperature_s16;
}

/*!
 *  @brief this API is used to calculate the true
 *  pressure using the uncompensated pressure(up)
 *  @note For reading the up data refer : bmp180_read_up()
 *
 *  @param v_uncomp_pressure_u32: the value of uncompensated pressure
 *
 *  @return Return the value of pressure in steps of 1.0 Pa
 *
 */
s32 bmp180_get_pressure(u32 v_uncomp_pressure_u32)
{
    s32 v_pressure_s32, v_x1_s32, v_x2_s32, v_x3_s32, v_b3_s32, v_b6_s32 = BMP180_INIT_VALUE;
    u32 v_b4_u32, v_b7_u32 = BMP180_INIT_VALUE;

    v_b6_s32 = p_bmp180->param_b5 - 4000;

    /*****calculate B3************/
    v_x1_s32 = (v_b6_s32 * v_b6_s32) >> BMP180_SHIFT_BIT_POSITION_BY_12_BITS;
    v_x1_s32 *= p_bmp180->calib_param.b2;
    v_x1_s32 >>= BMP180_SHIFT_BIT_POSITION_BY_11_BITS;
    v_x2_s32 = (p_bmp180->calib_param.ac2 * v_b6_s32);
    v_x2_s32 >>= BMP180_SHIFT_BIT_POSITION_BY_11_BITS;
    v_x3_s32 = v_x1_s32 + v_x2_s32;
    v_b3_s32 = (((((s32)p_bmp180->calib_param.ac1) * 4 + v_x3_s32) << p_bmp180->oversamp_setting) + 2) >>
               BMP180_SHIFT_BIT_POSITION_BY_02_BITS;

    /*****calculate B4************/
    v_x1_s32 = (p_bmp180->calib_param.ac3 * v_b6_s32) >> BMP180_SHIFT_BIT_POSITION_BY_13_BITS;
    v_x2_s32 = (p_bmp180->calib_param.b1 * ((v_b6_s32 * v_b6_s32) >> BMP180_SHIFT_BIT_POSITION_BY_12_BITS)) >>
               BMP180_SHIFT_BIT_POSITION_BY_16_BITS;
    v_x3_s32 = ((v_x1_s32 + v_x2_s32) + 2) >> BMP180_SHIFT_BIT_POSITION_BY_02_BITS;
    v_b4_u32 = (p_bmp180->calib_param.ac4 * (u32)(v_x3_s32 + 32768)) >> BMP180_SHIFT_BIT_POSITION_BY_15_BITS;
    v_b7_u32 = ((u32)(v_uncomp_pressure_u32 - v_b3_s32) * (50000 >> p_bmp180->oversamp_setting));
    if (v_b7_u32 < 0x80000000)
    {
        if (v_b4_u32 != BMP180_CHECK_DIVISOR)
        {
            v_pressure_s32 = (v_b7_u32 << BMP180_SHIFT_BIT_POSITION_BY_01_BIT) / v_b4_u32;
        }
        else
        {
            return BMP180_INVALID_DATA;
        }
    }
    else
    {
        if (v_b4_u32 != BMP180_CHECK_DIVISOR)
        {
            v_pressure_s32 = (v_b7_u32 / v_b4_u32) << BMP180_SHIFT_BIT_POSITION_BY_01_BIT;
        }
        else
        {
            return BMP180_INVALID_DATA;
        }
    }
    v_x1_s32 = v_pressure_s32 >> BMP180_SHIFT_BIT_POSITION_BY_08_BITS;
    v_x1_s32 *= v_x1_s32;
    v_x1_s32 = (v_x1_s32 * BMP180_PARAM_MG) >> BMP180_SHIFT_BIT_POSITION_BY_16_BITS;
    v_x2_s32 = (v_pressure_s32 * BMP180_PARAM_MH) >> BMP180_SHIFT_BIT_POSITION_BY_16_BITS;

    /*pressure in Pa*/
    v_pressure_s32 += (v_x1_s32 + v_x2_s32 + BMP180_PARAM_MI) >> BMP180_SHIFT_BIT_POSITION_BY_04_BITS;

    return v_pressure_s32;
}

/*!
 *  @brief this API is used to read the
 *  uncompensated temperature(ut) from the register
 *  @note 0xF6(MSB) bit from 0 to 7
 *  @note 0xF7(LSB) bit from 0 to 7
 *
 *
 *  @return results of bus communication function
 *  @retval 0 -> Success
 *  @retval -1 -> Error
 *
 *
 */
u16 bmp180_get_uncomp_temperature(void)
{
    u16 v_ut_u16 = BMP180_INIT_VALUE;

    /* Array holding the temperature LSB and MSB data*/
    u8 v_data_u8[BMP180_TEMPERATURE_DATA_BYTES] = { BMP180_INIT_VALUE, BMP180_INIT_VALUE };
    u8 v_ctrl_reg_data_u8 = BMP180_INIT_VALUE;

    /* used to return the bus communication results*/
    BMP180_RETURN_FUNCTION_TYPE v_com_rslt_s8 = E_BMP_COMM_RES;
    u8 v_wait_time_u8 = BMP180_INIT_VALUE;

    v_ctrl_reg_data_u8 = BMP180_T_MEASURE;
    v_wait_time_u8 = BMP180_TEMP_CONVERSION_TIME;
    v_com_rslt_s8 = p_bmp180->BMP180_BUS_WRITE_FUNC(p_bmp180->dev_addr,
                                                    BMP180_CTRL_MEAS_REG,
                                                    &v_ctrl_reg_data_u8,
                                                    BMP180_GEN_READ_WRITE_DATA_LENGTH);
    p_bmp180->delay_msec(v_wait_time_u8);
    v_com_rslt_s8 += p_bmp180->BMP180_BUS_READ_FUNC(p_bmp180->dev_addr,
                                                    BMP180_ADC_OUT_MSB_REG,
                                                    v_data_u8,
                                                    BMP180_TEMPERATURE_DATA_LENGTH);
    if (v_com_rslt_s8 == 0)
    {
        v_ut_u16 =
            (u16)((((s32)((s8)v_data_u8[BMP180_TEMPERATURE_MSB_DATA])) << BMP180_SHIFT_BIT_POSITION_BY_08_BITS) |
                  (v_data_u8[BMP180_TEMPERATURE_LSB_DATA]));
    }

    return v_ut_u16;
}

/*!
 *  @brief this API is used to read the
 *  uncompensated pressure(up) from the register
 *  @note 0xF6(MSB) bit from 0 to 7
 *  @note 0xF7(LSB) bit from 0 to 7
 *  @note 0xF8(LSB) bit from 3 to 7
 *
 *
 *  @return results of bus communication function
 *  @retval 0 -> Success
 *  @retval -1 -> Error
 *
 */
u32 bmp180_get_uncomp_pressure(void)
{
    /*j included for loop*/
    u8 v_j_u8 = BMP180_INIT_VALUE;
    u32 v_up_u32 = BMP180_INIT_VALUE;

    /*get the calculated pressure data*/
    u32 v_sum_u32 = BMP180_INIT_VALUE;
    u8 v_data_u8[BMP180_PRESSURE_DATA_BYTES] = { BMP180_INIT_VALUE, BMP180_INIT_VALUE, BMP180_INIT_VALUE };
    u8 v_ctrl_reg_data_u8 = BMP180_INIT_VALUE;

    /* used to return the bus communication results*/
    BMP180_RETURN_FUNCTION_TYPE v_com_rslt_s8 = E_BMP_COMM_RES;

    if (p_bmp180->sw_oversamp == BMP180_SW_OVERSAMP_U8X && p_bmp180->oversamp_setting == BMP180_OVERSAMP_SETTING_U8X)
    {
        for (v_j_u8 = BMP180_INIT_VALUE; v_j_u8 < BMP180_DATA_MEASURE; v_j_u8++)
        {
            /* 3 times getting pressure data*/
            v_ctrl_reg_data_u8 = BMP180_P_MEASURE +
                                 (p_bmp180->oversamp_setting << BMP180_SHIFT_BIT_POSITION_BY_06_BITS);
            v_com_rslt_s8 = p_bmp180->BMP180_BUS_WRITE_FUNC(p_bmp180->dev_addr,
                                                            BMP180_CTRL_MEAS_REG,
                                                            &v_ctrl_reg_data_u8,
                                                            BMP180_GEN_READ_WRITE_DATA_LENGTH);
            p_bmp180->delay_msec(BMP180_2MS_DELAY_U8X + (BMP180_3MS_DELAY_U8X << (p_bmp180->oversamp_setting)));
            v_com_rslt_s8 += p_bmp180->BMP180_BUS_READ_FUNC(p_bmp180->dev_addr,
                                                            BMP180_ADC_OUT_MSB_REG,
                                                            v_data_u8,
                                                            BMP180_PRESSURE_DATA_LENGTH);
            if (v_com_rslt_s8 == 0)
            {
                v_sum_u32 =
                    (u32)((((u32)v_data_u8[BMP180_PRESSURE_MSB_DATA] << BMP180_SHIFT_BIT_POSITION_BY_16_BITS) |
                           ((u32) v_data_u8[BMP180_PRESSURE_LSB_DATA] << BMP180_SHIFT_BIT_POSITION_BY_08_BITS) |
                           (u32) v_data_u8[BMP180_PRESSURE_XLSB_DATA]) >>
                          (BMP180_CALCULATE_TRUE_PRESSURE - p_bmp180->oversamp_setting));
                p_bmp180->number_of_samples = BMP180_INITIALIZE_NUMBER_OF_SAMPLES_U8X;
                v_up_u32 = v_up_u32 + v_sum_u32;
            }

            /*add up with dummy var*/
        }
        v_up_u32 = v_up_u32 / BMP180_AVERAGE_U8X; /*averaging*/
    }
    else if (p_bmp180->sw_oversamp == BMP180_INITIALIZE_SW_OVERSAMP_U8X)
    {
        v_ctrl_reg_data_u8 = BMP180_P_MEASURE + (p_bmp180->oversamp_setting << BMP180_SHIFT_BIT_POSITION_BY_06_BITS);
        v_com_rslt_s8 = p_bmp180->BMP180_BUS_WRITE_FUNC(p_bmp180->dev_addr,
                                                        BMP180_CTRL_MEAS_REG,
                                                        &v_ctrl_reg_data_u8,
                                                        BMP180_GEN_READ_WRITE_DATA_LENGTH);
        p_bmp180->delay_msec(BMP180_2MS_DELAY_U8X + (BMP180_3MS_DELAY_U8X << (p_bmp180->oversamp_setting)));
        v_com_rslt_s8 += p_bmp180->BMP180_BUS_READ_FUNC(p_bmp180->dev_addr,
                                                        BMP180_ADC_OUT_MSB_REG,
                                                        v_data_u8,
                                                        BMP180_PRESSURE_DATA_LENGTH);
        if (v_com_rslt_s8 == 0)
        {
            v_up_u32 =
                (u32)((((u32)v_data_u8[BMP180_PRESSURE_MSB_DATA] << BMP180_SHIFT_BIT_POSITION_BY_16_BITS) |
                       ((u32) v_data_u8[BMP180_PRESSURE_LSB_DATA] << BMP180_SHIFT_BIT_POSITION_BY_08_BITS) |
                       (u32) v_data_u8[BMP180_PRESSURE_XLSB_DATA]) >>
                      (BMP180_CALCULATE_TRUE_PRESSURE - p_bmp180->oversamp_setting));
            p_bmp180->number_of_samples = BMP180_INITIALIZE_NUMBER_OF_SAMPLES_U8X;
        }
    }

    return v_up_u32;
}
```

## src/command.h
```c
#pragma once

typedef enum {
	COMMAND_ID_SETTING,
	COMMAND_ID_CONFIRM,
	COMMAND_OP_START,
	COMMAND_OP_STOP,
	COMMAND_OP_PAUSE_RESUME,
	COMMAND_OP_POWER_OFF,
	COMMAND_SET_HEATER,
	COMMAND_SET_MOTOR,
	COMMAND_SET_MEASURE,
	COMMAND_SET_PATTERN,
	COMMAND_SET_LEVEL,
	MAX_COMMAND_TYPE
} CommandType;
```

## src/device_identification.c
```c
#include "device_identification.h"
#include <zephyr/posix/arpa/inet.h>
#include "protocol.h"

static uint16_t login_id;
static ProtocolHandler id_setting_handler, id_confirm_handler;

int setting(ProtocolDataUnit *pdu)
{
    if (pdu->command != id_setting_handler.command) {
        return -1;
    }
    login_id = NTOH_UINT16(pdu->params);
    return 0;
}

int confirm(ProtocolDataUnit *pdu)
{
    if (pdu->command != id_confirm_handler.command) {
        return -1;
    }
    uint16_t *response = (uint16_t *)pdu->params;
    if (*response) {
        // must be empty on received
        return -1;
    }
    *response = HTON_UINT16(&login_id);
    return 0;
}

void DeviceIdentification_init(void)
{
    id_setting_handler.command = 0x55AA;
    id_setting_handler.handler = setting;
    id_confirm_handler.command = 0xAA55;
    id_confirm_handler.handler = confirm;
    Protocol_set_handler(COMMAND_ID_SETTING, &id_setting_handler);
    Protocol_set_handler(COMMAND_ID_CONFIRM, &id_confirm_handler);
}
```

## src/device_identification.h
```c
#pragma once

void DeviceIdentification_init(void);
```

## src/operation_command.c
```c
#include "device_identification.h"
#include <zephyr/posix/arpa/inet.h>
#include "protocol.h"

static ProtocolHandler start_handler, stop_handler;
static ProtocolHandler pause_resume_handler, power_off_handler;

bool is_paused = false;

extern void start_vibration(void);
extern void stop_vibration(void);
extern void start_heater(void);
extern void stop_heater(void);
extern void start_measure(void);
extern void stop_measure(void);

static void start_operation_mode(void)
{
    start_measure();
    start_vibration();
    start_heater();
}

static void stop_operation_mode(void)
{
    stop_measure();
    stop_vibration();
    stop_heater();
}

int start(ProtocolDataUnit *pdu)
{
    start_operation_mode();
    if (pdu->command != start_handler.command) {
        return -1;
    }
    return 0;
}

int stop(ProtocolDataUnit *pdu)
{
    stop_operation_mode();
    if (pdu->command != stop_handler.command) {
        return -1;
    }
    return 0;
}

int pause_resume(ProtocolDataUnit *pdu)
{
    if (pdu->command != pause_resume_handler.command) {
        return -1;
    }
    is_paused = !is_paused;
    if (is_paused) {
        stop_operation_mode();
    } else {
        start_operation_mode();
    }
    return 0;
}

int power_off(ProtocolDataUnit *pdu)
{
    if (pdu->command != power_off_handler.command) {
        return -1;
    }
    return 0;
}

void OperationCommand_init(void)
{
    start_handler.command = 0x01FE;
    start_handler.handler = start;
    stop_handler.command = 0x02FD;
    stop_handler.handler = stop;
    pause_resume_handler.command = 0x04FB;
    pause_resume_handler.handler = pause_resume;
    power_off_handler.command = 0x08F7;
    power_off_handler.handler = power_off;
    Protocol_set_handler(COMMAND_OP_START, &start_handler);
    Protocol_set_handler(COMMAND_OP_STOP, &stop_handler);
    Protocol_set_handler(COMMAND_OP_PAUSE_RESUME, &pause_resume_handler);
    Protocol_set_handler(COMMAND_OP_POWER_OFF, &power_off_handler);
    start_operation_mode();
}
```

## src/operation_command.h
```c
#pragma once

void OperationCommand_init(void);
```

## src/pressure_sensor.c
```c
#include <zephyr/types.h>
#include <zephyr/kernel.h>
#include <zephyr/device.h>
#include <zephyr/devicetree.h>
#include <soc.h>

#include <hal/nrf_twi.h>
#include <zephyr/drivers/i2c.h>
#include <BMP180_driver/bmp180.h>

#define I2C_NAME DT_NODELABEL(i2c0)
#define I2C_CFG (I2C_SPEED_SET(I2C_SPEED_FAST) | I2C_MODE_CONTROLLER)
#define ASSERT(expr) if (expr) __BKPT(0)

static const struct device *i2c_dev;
uint32_t pressure;
float temperature;

void BMP180_delay_msek(uint32_t msek)
{
    k_sleep(K_MSEC(msek));
}

s8 BMP180_I2C_bus_read(u8 dev_addr, u8 reg_addr, u8 *reg_data, u8 cnt)
{
    return i2c_burst_read(i2c_dev, dev_addr, reg_addr, reg_data, cnt);
}

s8 BMP180_I2C_bus_write(u8 dev_addr, u8 reg_addr, u8 *reg_data, u8 cnt)
{
    return i2c_burst_write(i2c_dev, dev_addr, reg_addr, reg_data, cnt);
}

static struct bmp180_t bmp180 = {
    .bus_write = BMP180_I2C_bus_write,
    .bus_read = BMP180_I2C_bus_read,
    .dev_addr = BMP180_I2C_ADDR,
    .delay_msec = BMP180_delay_msek,
};

static void read_sensor(struct k_work *work)
{
    u32 v_uncomp_press_u32 = bmp180_get_uncomp_pressure();
    pressure = bmp180_get_pressure(v_uncomp_press_u32);
    
    u16 v_uncomp_temp_u16 = bmp180_get_uncomp_temperature();
    temperature = bmp180_get_temperature(v_uncomp_temp_u16);
}

K_WORK_DEFINE(work, read_sensor);

void PressureSensor_init(void)
{
    i2c_dev = DEVICE_DT_GET(I2C_NAME);
    while(!device_is_ready(i2c_dev));
    ASSERT(i2c_configure(i2c_dev, I2C_CFG));
    ASSERT(bmp180_init(&bmp180));
    ASSERT(bmp180_get_calib_param());
    read_sensor(&work);
}

uint8_t PressureSensor_read(void)
{
    k_work_submit(&work);

    // Typically around 103,000 Pa (above 90,000)
    // convert 103,000 to 13 to fit in UINT8_MAX
    return MIN(pressure / 1000 - 90, UINT8_MAX);
}

float PressureSensor_temp(void)
{
    k_work_submit(&work);

    return (temperature / 10);
}
```

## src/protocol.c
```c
#include "protocol.h"
#include <zephyr/kernel.h>

static ProtocolHandler *handlers[MAX_COMMAND_TYPE];

ProtocolDataUnit *Protocol_new_pdu(uint8_t *data, size_t len)
{
	uint16_t command = NTOH_UINT16(data);
	for (int i = 0; i < MAX_COMMAND_TYPE; i++) {
		if (handlers[i]->command == command) {
            ProtocolDataUnit *pdu = k_malloc(sizeof(*pdu));
            if (!pdu) {
                break;
            }
            pdu->command = command;
            pdu->params = data + sizeof(command);
			return pdu;
		}
	}
	return NULL;
}

void Protocol_delete_pdu(ProtocolDataUnit *pdu)
{
	k_free(pdu);
}

void Protocol_set_handler(CommandType command_type, ProtocolHandler *handler)
{
	handlers[command_type] = handler;
}

int Protocol_handle(ProtocolDataUnit *pdu)
{
	for (int i = 0; i < MAX_COMMAND_TYPE; i++) {
		if (handlers[i]->command == pdu->command) {
			return handlers[i]->handler(pdu);
		}
	}
	return 0;
}
```

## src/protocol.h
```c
#pragma once
#include <stddef.h>
#include <stdint.h>
#include <stdbool.h>
#include <zephyr/posix/arpa/inet.h>
#include "command.h"

#define NTOH_UINT16(data) ntohs(*(uint16_t *)data)
#define HTON_UINT16(data) htons(*(uint16_t *)data)

typedef struct {
    uint16_t command;
    uint8_t *params;
} ProtocolDataUnit;

typedef struct {
    uint16_t command;
    int (*handler)(ProtocolDataUnit *);
} ProtocolHandler;

ProtocolDataUnit *Protocol_new_pdu(uint8_t *data, size_t len);
void Protocol_delete_pdu(ProtocolDataUnit *pdu);
void Protocol_set_handler(CommandType command_type, ProtocolHandler *handler);
int Protocol_handle(ProtocolDataUnit *pdu);
```

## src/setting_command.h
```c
#pragma once

void SettingCommand_init(void);
```
